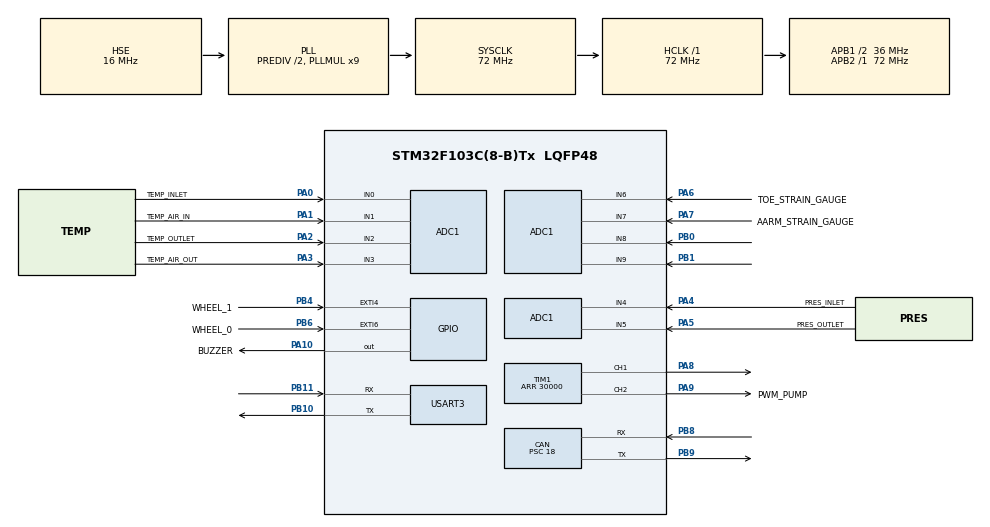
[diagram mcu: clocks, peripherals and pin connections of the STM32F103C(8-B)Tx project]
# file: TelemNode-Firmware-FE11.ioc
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ADC1.Channel-2\#ChannelRegularConversion=ADC_CHANNEL_0
ADC1.ContinuousConvMode=DISABLE
ADC1.EnableRegularConversion=ENABLE
ADC1.NbrOfConversion=1
ADC1.NbrOfConversionFlag=1
ADC1.Rank-2\#ChannelRegularConversion=1
ADC1.SamplingTime-2\#ChannelRegularConversion=ADC_SAMPLETIME_1CYCLE_5
ADC1.master=1
CAN.BS1=CAN_BS1_2TQ
CAN.CalculateBaudRate=500000
CAN.CalculateTimeBit=2000
CAN.CalculateTimeQuantum=500.0
CAN.Mode=CAN_MODE_NORMAL
CAN.NART=ENABLE
CAN.Prescaler=18
Mcu.Family=STM32F1
Mcu.Name=STM32F103C(8-B)Tx
Mcu.Package=LQFP48
NVIC.EXTI9_5_IRQn=true\:0\:0\:false\:false\:true\:true\:true\:true
NVIC.PriorityGroup=NVIC_PRIORITYGROUP_4
NVIC.USB_LP_CAN1_RX0_IRQn=true\:0\:0\:false\:false\:true\:true\:true\:true
PA0-WKUP.GPIO_Label=TEMP_INLET
PA0-WKUP.Signal=ADCx_IN0
PA1.GPIO_Label=TEMP_AIR_IN
PA1.Signal=ADCx_IN1
PA10.GPIO_Label=BUZZER
PA10.GPIO_ModeDefaultOutputPP=GPIO_MODE_OUTPUT_OD
PA10.GPIO_PuPd=GPIO_NOPULL
PA10.Signal=GPIO_Output
PA13.Mode=Serial_Wire
PA13.Signal=SYS_JTMS-SWDIO
PA14.Mode=Serial_Wire
PA14.Signal=SYS_JTCK-SWCLK
PA15.Signal=SYS_JTDI
PA2.GPIO_Label=TEMP_OUTLET
PA2.Signal=ADCx_IN2
PA3.GPIO_Label=TEMP_AIR_OUT
PA3.Signal=ADCx_IN3
PA4.GPIO_Label=PRES_INLET
PA4.Signal=ADCx_IN4
PA5.GPIO_Label=PRES_OUTLET
PA5.Signal=ADCx_IN5
PA6.GPIO_Label=TOE_STRAIN_GAUGE
PA6.Signal=ADCx_IN6
PA7.GPIO_Label=AARM_STRAIN_GAUGE
PA7.Signal=ADCx_IN7
PA8.Signal=S_TIM1_CH1
PA9.GPIO_Label=PWM_PUMP
PA9.GPIO_ModeDefaultPP=GPIO_MODE_AF_OD
PA9.Signal=S_TIM1_CH2
PB0.Signal=ADCx_IN8
PB1.Signal=ADCx_IN9
PB10.Mode=Asynchronous
PB10.Signal=USART3_TX
PB11.Mode=Asynchronous
PB11.Signal=USART3_RX
PB3.Signal=SYS_JTDO-TRACESWO
PB4.GPIO_Label=WHEEL_1
PB4.Signal=GPXTI4
PB6.GPIO_Label=WHEEL_0
PB6.Signal=GPXTI6
PB8.GPIO_PuPd=GPIO_PULLUP
PB8.Mode=CAN_Activate
PB8.Signal=CAN_RX
PB9.Mode=CAN_Activate
PB9.Signal=CAN_TX
PD0-OSC_IN.Mode=HSE-External-Oscillator
PD0-OSC_IN.Signal=RCC_OSC_IN
PD1-OSC_OUT.Mode=HSE-External-Oscillator
PD1-OSC_OUT.Signal=RCC_OSC_OUT
ProjectManager.HeapSize=0x200
ProjectManager.StackSize=0x400
ProjectManager.TargetToolchain=STM32CubeIDE
RCC.ADCPresc=RCC_ADCPCLK2_DIV8
RCC.AHBFreq_Value=72000000
RCC.APB1CLKDivider=RCC_HCLK_DIV2
RCC.APB1Freq_Value=36000000
RCC.APB1TimFreq_Value=72000000
RCC.APB2Freq_Value=72000000
RCC.APB2TimFreq_Value=72000000
RCC.HCLKFreq_Value=72000000
RCC.HSEDivPLL=RCC_HSE_PREDIV_DIV2
RCC.HSE_VALUE=16000000
RCC.PLLMUL=RCC_PLL_MUL9
RCC.PLLSourceVirtual=RCC_PLLSOURCE_HSE
RCC.SYSCLKFreq_VALUE=72000000
RCC.SYSCLKSource=RCC_SYSCLKSOURCE_PLLCLK
RCC.USBFreq_Value=72000000
SH.ADCx_IN0.0=ADC1_IN0,IN0
SH.ADCx_IN1.0=ADC1_IN1,IN1
SH.ADCx_IN2.0=ADC1_IN2,IN2
SH.ADCx_IN3.0=ADC1_IN3,IN3
SH.ADCx_IN4.0=ADC1_IN4,IN4
SH.ADCx_IN5.0=ADC1_IN5,IN5
SH.ADCx_IN6.0=ADC1_IN6,IN6
SH.ADCx_IN7.0=ADC1_IN7,IN7
SH.ADCx_IN8.0=ADC1_IN8,IN8
SH.ADCx_IN9.0=ADC1_IN9,IN9
SH.S_TIM1_CH1.0=TIM1_CH1,PWM Generation1 CH1
SH.S_TIM1_CH2.0=TIM1_CH2,PWM Generation2 CH2
TIM1.Channel-PWM\ Generation1\ CH1=TIM_CHANNEL_1
TIM1.Channel-PWM\ Generation2\ CH2=TIM_CHANNEL_2
TIM1.CounterMode=TIM_COUNTERMODE_UP
TIM1.Period=30000
USART3.VirtualMode=VM_ASYNC
VP_TIM1_VS_ClockSourceINT.Mode=Internal
board=custom

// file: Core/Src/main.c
/* USER CODE BEGIN Header */
/**
  ******************************************************************************
  * @file           : main.c
  * @brief          : Main program body
  ******************************************************************************
  * @attention
  *
  * Copyright (c) 2024 STMicroelectronics.
  * All rights reserved.
  *
  * This software is licensed under terms that can be found in the LICENSE file
  * in the root directory of this software component.
  * If no LICENSE file comes with this software, it is provided AS-IS.
  *
  ******************************************************************************
  */
/* USER CODE END Header */
#include "main.h"

/* USER CODE BEGIN Includes */

#include "telem_node.h"

/* USER CODE END Includes */

ADC_HandleTypeDef hadc1;

CAN_HandleTypeDef hcan;

TIM_HandleTypeDef htim1;

UART_HandleTypeDef huart3;

void SystemClock_Config(void);
static void MX_GPIO_Init(void);
static void MX_CAN_Init(void);
static void MX_TIM1_Init(void);
static void MX_ADC1_Init(void);
static void MX_USART3_UART_Init(void);

int main(void)
{

  /* MCU Configuration--------------------------------------------------------*/

  /* Reset of all peripherals, Initializes the Flash interface and the Systick. */
  HAL_Init();

  /* Configure the system clock */
  SystemClock_Config();

  /* Initialize all configured peripherals */
  MX_GPIO_Init();
  MX_CAN_Init();
  MX_TIM1_Init();
  MX_ADC1_Init();
  MX_USART3_UART_Init();
  /* USER CODE BEGIN 2 */

  TelemNode_Init();

  /* USER CODE END 2 */

  /* Infinite loop */
  /* USER CODE BEGIN WHILE */
  while (1)
  {
	  TelemNode_Update();

    /* USER CODE END WHILE */

  }
}

void SystemClock_Config(void)
{
  RCC_OscInitTypeDef RCC_OscInitStruct = {0};
  RCC_ClkInitTypeDef RCC_ClkInitStruct = {0};
  RCC_PeriphCLKInitTypeDef PeriphClkInit = {0};

  /** Initializes the RCC Oscillators according to the specified parameters
  * in the RCC_OscInitTypeDef structure.
  */
  RCC_OscInitStruct.OscillatorType = RCC_OSCILLATORTYPE_HSE;
  RCC_OscInitStruct.HSEState = RCC_HSE_ON;
  RCC_OscInitStruct.HSEPredivValue = RCC_HSE_PREDIV_DIV2;
  RCC_OscInitStruct.HSIState = RCC_HSI_ON;
  RCC_OscInitStruct.PLL.PLLState = RCC_PLL_ON;
  RCC_OscInitStruct.PLL.PLLSource = RCC_PLLSOURCE_HSE;
  RCC_OscInitStruct.PLL.PLLMUL = RCC_PLL_MUL9;
  if (HAL_RCC_OscConfig(&RCC_OscInitStruct) != HAL_OK)
  {
    Error_Handler();
  }

  /** Initializes the CPU, AHB and APB buses clocks
  */
  RCC_ClkInitStruct.ClockType = RCC_CLOCKTYPE_HCLK|RCC_CLOCKTYPE_SYSCLK
                              |RCC_CLOCKTYPE_PCLK1|RCC_CLOCKTYPE_PCLK2;
  RCC_ClkInitStruct.SYSCLKSource = RCC_SYSCLKSOURCE_PLLCLK;
  RCC_ClkInitStruct.AHBCLKDivider = RCC_SYSCLK_DIV1;
  RCC_ClkInitStruct.APB1CLKDivider = RCC_HCLK_DIV2;
  RCC_ClkInitStruct.APB2CLKDivider = RCC_HCLK_DIV1;

  if (HAL_RCC_ClockConfig(&RCC_ClkInitStruct, FLASH_LATENCY_2) != HAL_OK)
  {
    Error_Handler();
  }
  PeriphClkInit.PeriphClockSelection = RCC_PERIPHCLK_ADC;
  PeriphClkInit.AdcClockSelection = RCC_ADCPCLK2_DIV8;
  if (HAL_RCCEx_PeriphCLKConfig(&PeriphClkInit) != HAL_OK)
  {
    Error_Handler();
  }
}

static void MX_ADC1_Init(void)
{

  ADC_ChannelConfTypeDef sConfig = {0};

  /** Common config
  */
  hadc1.Instance = ADC1;
  hadc1.Init.ScanConvMode = ADC_SCAN_DISABLE;
  hadc1.Init.ContinuousConvMode = DISABLE;
  hadc1.Init.DiscontinuousConvMode = DISABLE;
  hadc1.Init.ExternalTrigConv = ADC_SOFTWARE_START;
  hadc1.Init.DataAlign = ADC_DATAALIGN_RIGHT;
  hadc1.Init.NbrOfConversion = 1;
  if (HAL_ADC_Init(&hadc1) != HAL_OK)
  {
    Error_Handler();
  }

  /** Configure Regular Channel
  */
  sConfig.Channel = ADC_CHANNEL_0;
  sConfig.Rank = ADC_REGULAR_RANK_1;
  sConfig.SamplingTime = ADC_SAMPLETIME_1CYCLE_5;
  if (HAL_ADC_ConfigChannel(&hadc1, &sConfig) != HAL_OK)
  {
    Error_Handler();
  }

}

static void MX_CAN_Init(void)
{

  hcan.Instance = CAN1;
  hcan.Init.Prescaler = 18;
  hcan.Init.Mode = CAN_MODE_NORMAL;
  hcan.Init.SyncJumpWidth = CAN_SJW_1TQ;
  hcan.Init.TimeSeg1 = CAN_BS1_2TQ;
  hcan.Init.TimeSeg2 = CAN_BS2_1TQ;
  hcan.Init.TimeTriggeredMode = DISABLE;
  hcan.Init.AutoBusOff = DISABLE;
  hcan.Init.AutoWakeUp = DISABLE;
  hcan.Init.AutoRetransmission = ENABLE;
  hcan.Init.ReceiveFifoLocked = DISABLE;
  hcan.Init.TransmitFifoPriority = DISABLE;
  if (HAL_CAN_Init(&hcan) != HAL_OK)
  {
    Error_Handler();
  }

}

static void MX_TIM1_Init(void)
{

  TIM_ClockConfigTypeDef sClockSourceConfig = {0};
  TIM_MasterConfigTypeDef sMasterConfig = {0};
  TIM_OC_InitTypeDef sConfigOC = {0};
  TIM_BreakDeadTimeConfigTypeDef sBreakDeadTimeConfig = {0};

  htim1.Instance = TIM1;
  htim1.Init.Prescaler = 0;
  htim1.Init.CounterMode = TIM_COUNTERMODE_UP;
  htim1.Init.Period = 30000;
  htim1.Init.ClockDivision = TIM_CLOCKDIVISION_DIV1;
  htim1.Init.RepetitionCounter = 0;
  htim1.Init.AutoReloadPreload = TIM_AUTORELOAD_PRELOAD_DISABLE;
  if (HAL_TIM_Base_Init(&htim1) != HAL_OK)
  {
    Error_Handler();
  }
  sClockSourceConfig.ClockSource = TIM_CLOCKSOURCE_INTERNAL;
  if (HAL_TIM_ConfigClockSource(&htim1, &sClockSourceConfig) != HAL_OK)
  {
    Error_Handler();
  }
  if (HAL_TIM_PWM_Init(&htim1) != HAL_OK)
  {
    Error_Handler();
  }
  sMasterConfig.MasterOutputTrigger = TIM_TRGO_RESET;
  sMasterConfig.MasterSlaveMode = TIM_MASTERSLAVEMODE_DISABLE;
  if (HAL_TIMEx_MasterConfigSynchronization(&htim1, &sMasterConfig) != HAL_OK)
  {
    Error_Handler();
  }
  sConfigOC.OCMode = TIM_OCMODE_PWM1;
  sConfigOC.Pulse = 0;
  sConfigOC.OCPolarity = TIM_OCPOLARITY_HIGH;
  sConfigOC.OCNPolarity = TIM_OCNPOLARITY_HIGH;
  sConfigOC.OCFastMode = TIM_OCFAST_DISABLE;
  sConfigOC.OCIdleState = TIM_OCIDLESTATE_RESET;
  sConfigOC.OCNIdleState = TIM_OCNIDLESTATE_RESET;
  if (HAL_TIM_PWM_ConfigChannel(&htim1, &sConfigOC, TIM_CHANNEL_1) != HAL_OK)
  {
    Error_Handler();
  }
  if (HAL_TIM_PWM_ConfigChannel(&htim1, &sConfigOC, TIM_CHANNEL_2) != HAL_OK)
  {
    Error_Handler();
  }
  sBreakDeadTimeConfig.OffStateRunMode = TIM_OSSR_DISABLE;
  sBreakDeadTimeConfig.OffStateIDLEMode = TIM_OSSI_DISABLE;
  sBreakDeadTimeConfig.LockLevel = TIM_LOCKLEVEL_OFF;
  sBreakDeadTimeConfig.DeadTime = 0;
  sBreakDeadTimeConfig.BreakState = TIM_BREAK_DISABLE;
  sBreakDeadTimeConfig.BreakPolarity = TIM_BREAKPOLARITY_HIGH;
  sBreakDeadTimeConfig.AutomaticOutput = TIM_AUTOMATICOUTPUT_DISABLE;
  if (HAL_TIMEx_ConfigBreakDeadTime(&htim1, &sBreakDeadTimeConfig) != HAL_OK)
  {
    Error_Handler();
  }
  HAL_TIM_MspPostInit(&htim1);

}

static void MX_USART3_UART_Init(void)
{

  huart3.Instance = USART3;
  huart3.Init.BaudRate = 115200;
  huart3.Init.WordLength = UART_WORDLENGTH_8B;
  huart3.Init.StopBits = UART_STOPBITS_1;
  huart3.Init.Parity = UART_PARITY_NONE;
  huart3.Init.Mode = UART_MODE_TX_RX;
  huart3.Init.HwFlowCtl = UART_HWCONTROL_NONE;
  huart3.Init.OverSampling = UART_OVERSAMPLING_16;
  if (HAL_UART_Init(&huart3) != HAL_OK)
  {
    Error_Handler();
  }

}

static void MX_GPIO_Init(void)
{
  GPIO_InitTypeDef GPIO_InitStruct = {0};

  /* GPIO Ports Clock Enable */
  __HAL_RCC_GPIOD_CLK_ENABLE();
  __HAL_RCC_GPIOA_CLK_ENABLE();
  __HAL_RCC_GPIOB_CLK_ENABLE();

  /*Configure GPIO pin Output Level */
  HAL_GPIO_WritePin(BUZZER_GPIO_Port, BUZZER_Pin, GPIO_PIN_RESET);

  /*Configure GPIO pin : BUZZER_Pin */
  GPIO_InitStruct.Pin = BUZZER_Pin;
  GPIO_InitStruct.Mode = GPIO_MODE_OUTPUT_OD;
  GPIO_InitStruct.Pull = GPIO_NOPULL;
  GPIO_InitStruct.Speed = GPIO_SPEED_FREQ_LOW;
  HAL_GPIO_Init(BUZZER_GPIO_Port, &GPIO_InitStruct);

  /*Configure GPIO pins : WHEEL_1_Pin WHEEL_0_Pin */
  GPIO_InitStruct.Pin = WHEEL_1_Pin|WHEEL_0_Pin;
  GPIO_InitStruct.Mode = GPIO_MODE_IT_RISING;
  GPIO_InitStruct.Pull = GPIO_NOPULL;
  HAL_GPIO_Init(GPIOB, &GPIO_InitStruct);

  /* EXTI interrupt init*/
  HAL_NVIC_SetPriority(EXTI9_5_IRQn, 0, 0);
  HAL_NVIC_EnableIRQ(EXTI9_5_IRQn);

}

void Error_Handler(void)
{
  __disable_irq();
  while (1)
  {
  }
}
